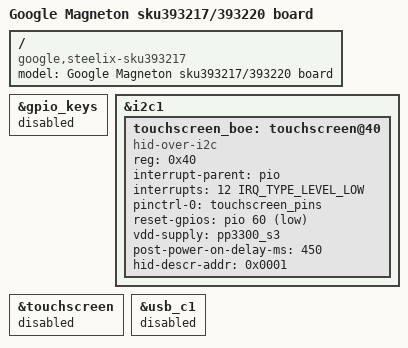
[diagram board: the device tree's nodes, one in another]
// SPDX-License-Identifier: (GPL-2.0 OR MIT)
/*
 * Copyright 2022 Google LLC
 */

/dts-v1/;
#include "mt8186-corsola-steelix.dtsi"

/ {
	model = "Google Magneton sku393217/393220 board";
	compatible = "google,steelix-sku393217", "google,steelix-sku393220",
		     "google,steelix", "mediatek,mt8186";
};

&gpio_keys {
	status = "disabled";
};

&i2c1 {
	touchscreen_boe: touchscreen@40 {
		compatible = "hid-over-i2c";
		reg = <0x40>;
		interrupt-parent = <&pio>;
		interrupts = <12 IRQ_TYPE_LEVEL_LOW>;
		pinctrl-names = "default";
		pinctrl-0 = <&touchscreen_pins>;
		reset-gpios = <&pio 60 GPIO_ACTIVE_LOW>;
		vdd-supply = <&pp3300_s3>;
		status = "okay";

		post-power-on-delay-ms = <450>;
		hid-descr-addr = <0x0001>;
	};
};

&touchscreen {
	status = "disabled";
};

&usb_c1 {
	status = "disabled";
};
